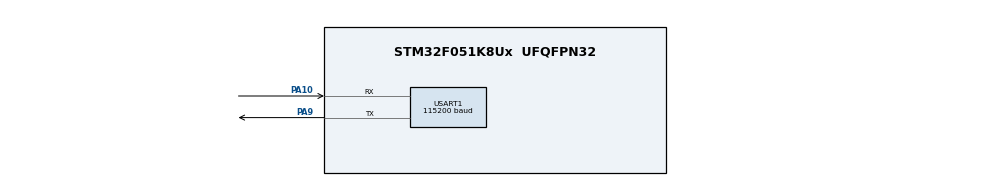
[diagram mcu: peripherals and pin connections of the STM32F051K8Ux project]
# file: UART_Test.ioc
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Mcu.Family=STM32F0
Mcu.Name=STM32F051K8Ux
Mcu.Package=UFQFPN32
PA10.Mode=Asynchronous
PA10.Signal=USART1_RX
PA9.Mode=Asynchronous
PA9.Signal=USART1_TX
ProjectManager.HeapSize=0x200
ProjectManager.StackSize=0x400
ProjectManager.TargetToolchain=MDK-ARM V5
USART1.BaudRate=115200
USART1.VirtualMode-Asynchronous=VM_ASYNC
board=UART_Test

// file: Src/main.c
/**
  ******************************************************************************
  * File Name          : main.c
  * Description        : Main program body
  ******************************************************************************
  ** This notice applies to any and all portions of this file
  * that are not between comment pairs USER CODE BEGIN and
  * USER CODE END. Other portions of this file, whether
  * inserted by the user or by software development tools
  * are owned by their respective copyright owners.
  *
  * COPYRIGHT(c) 2020 STMicroelectronics
  *
  * Redistribution and use in source and binary forms, with or without modification,
  * are permitted provided that the following conditions are met:
  *   1. Redistributions of source code must retain the above copyright notice,
  *      this list of conditions and the following disclaimer.
  *   2. Redistributions in binary form must reproduce the above copyright notice,
  *      this list of conditions and the following disclaimer in the documentation
  *      and/or other materials provided with the distribution.
  *   3. Neither the name of STMicroelectronics nor the names of its contributors
  *      may be used to endorse or promote products derived from this software
  *      without specific prior written permission.
  *
  * THIS SOFTWARE IS PROVIDED BY THE COPYRIGHT HOLDERS AND CONTRIBUTORS "AS IS"
  * AND ANY EXPRESS OR IMPLIED WARRANTIES, INCLUDING, BUT NOT LIMITED TO, THE
  * IMPLIED WARRANTIES OF MERCHANTABILITY AND FITNESS FOR A PARTICULAR PURPOSE ARE
  * DISCLAIMED. IN NO EVENT SHALL THE COPYRIGHT HOLDER OR CONTRIBUTORS BE LIABLE
  * FOR ANY DIRECT, INDIRECT, INCIDENTAL, SPECIAL, EXEMPLARY, OR CONSEQUENTIAL
  * DAMAGES (INCLUDING, BUT NOT LIMITED TO, PROCUREMENT OF SUBSTITUTE GOODS OR
  * SERVICES; LOSS OF USE, DATA, OR PROFITS; OR BUSINESS INTERRUPTION) HOWEVER
  * CAUSED AND ON ANY THEORY OF LIABILITY, WHETHER IN CONTRACT, STRICT LIABILITY,
  * OR TORT (INCLUDING NEGLIGENCE OR OTHERWISE) ARISING IN ANY WAY OUT OF THE USE
  * OF THIS SOFTWARE, EVEN IF ADVISED OF THE POSSIBILITY OF SUCH DAMAGE.
  *
  ******************************************************************************
  */
#include "main.h"
#include "stm32f0xx_hal.h"
#include "usart.h"
#include "gpio.h"

/* USER CODE BEGIN Includes */
#include <string.h>
#include <stdio.h>
/* USER CODE END Includes */

/* USER CODE BEGIN PV */
/* Private variables ---------------------------------------------------------*/

/* USER CODE END PV */

void SystemClock_Config(void);

/* USER CODE BEGIN PFP */
/* Private function prototypes -----------------------------------------------*/

/* USER CODE END PFP */

int main(void)
{

  /* USER CODE BEGIN 1 */
	uint8_t buffer[32] = {0};
//	int back;
  /* USER CODE END 1 */

  /* MCU Configuration----------------------------------------------------------*/

  /* Reset of all peripherals, Initializes the Flash interface and the Systick. */
  HAL_Init();

  /* Configure the system clock */
  SystemClock_Config();

  /* Initialize all configured peripherals */
  MX_GPIO_Init();
  MX_USART1_UART_Init();

  /* Infinite loop */
  while (1)
  {
//	  while(back = HAL_UART_Receive(&huart1, buffer, 32, 1000)){
//		  if(back == HAL_ERROR){
//			HAL_UART_Transmit(&huart1, "HAL_ERROR!\n", sizeof("HAL_ERROR!\n"), 100);
//		  }
//		  else if(back == HAL_TIMEOUT){
//			  HAL_UART_Transmit(&huart1, "HAL_TIMEOUT!\n", sizeof("HAL_TIMEOUT!\n"), 100);
//		  }
//		  else if(back == HAL_BUSY){
//			  HAL_UART_Transmit(&huart1, "HAL_BUSY!\n", sizeof("HAL_BUSY!\n"), 100);
//		  }
//		  else{
//			  HAL_UART_Transmit(&huart1, "HAL_OK!\n", sizeof("HAL_OK!\n"), 100);
//		  }
//	  }

//	  HAL_UART_Receive(&huart1, buffer, 32, 1000);
	  scanf("%s", buffer);
	  HAL_Delay(100);
	  HAL_UART_Transmit(&huart1, buffer, sizeof(buffer), 1000);
	  HAL_Delay(100);

  }

}

/** System Clock Configuration
*/
void SystemClock_Config(void)
{

  RCC_OscInitTypeDef RCC_OscInitStruct;
  RCC_ClkInitTypeDef RCC_ClkInitStruct;
  RCC_PeriphCLKInitTypeDef PeriphClkInit;

    /**Initializes the CPU, AHB and APB busses clocks
    */
  RCC_OscInitStruct.OscillatorType = RCC_OSCILLATORTYPE_HSI;
  RCC_OscInitStruct.HSIState = RCC_HSI_ON;
  RCC_OscInitStruct.HSICalibrationValue = 16;
  RCC_OscInitStruct.PLL.PLLState = RCC_PLL_NONE;
  if (HAL_RCC_OscConfig(&RCC_OscInitStruct) != HAL_OK)
  {
    _Error_Handler(__FILE__, __LINE__);
  }

    /**Initializes the CPU, AHB and APB busses clocks
    */
  RCC_ClkInitStruct.ClockType = RCC_CLOCKTYPE_HCLK|RCC_CLOCKTYPE_SYSCLK
                              |RCC_CLOCKTYPE_PCLK1;
  RCC_ClkInitStruct.SYSCLKSource = RCC_SYSCLKSOURCE_HSI;
  RCC_ClkInitStruct.AHBCLKDivider = RCC_SYSCLK_DIV1;
  RCC_ClkInitStruct.APB1CLKDivider = RCC_HCLK_DIV1;

  if (HAL_RCC_ClockConfig(&RCC_ClkInitStruct, FLASH_LATENCY_0) != HAL_OK)
  {
    _Error_Handler(__FILE__, __LINE__);
  }

  PeriphClkInit.PeriphClockSelection = RCC_PERIPHCLK_USART1;
  PeriphClkInit.Usart1ClockSelection = RCC_USART1CLKSOURCE_PCLK1;
  if (HAL_RCCEx_PeriphCLKConfig(&PeriphClkInit) != HAL_OK)
  {
    _Error_Handler(__FILE__, __LINE__);
  }

    /**Configure the Systick interrupt time
    */
  HAL_SYSTICK_Config(HAL_RCC_GetHCLKFreq()/1000);

    /**Configure the Systick
    */
  HAL_SYSTICK_CLKSourceConfig(SYSTICK_CLKSOURCE_HCLK);

  /* SysTick_IRQn interrupt configuration */
  HAL_NVIC_SetPriority(SysTick_IRQn, 0, 0);
}

void _Error_Handler(char * file, int line)
{
  while(1)
  {
  }
}

/************************ (C) COPYRIGHT STMicroelectronics *****END OF FILE****/
